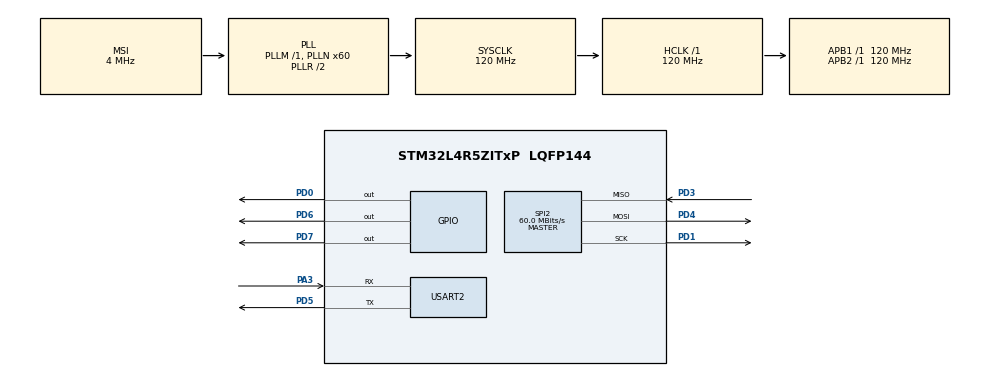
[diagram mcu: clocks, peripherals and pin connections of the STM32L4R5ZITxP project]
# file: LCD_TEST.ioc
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Mcu.Family=STM32L4
Mcu.Name=STM32L4R5ZITxP
Mcu.Package=LQFP144
NVIC.PriorityGroup=NVIC_PRIORITYGROUP_4
PA3.Mode=Asynchronous
PA3.Signal=USART2_RX
PD0.Signal=GPIO_Output
PD1.Mode=Full_Duplex_Master
PD1.Signal=SPI2_SCK
PD3.Mode=Full_Duplex_Master
PD3.Signal=SPI2_MISO
PD4.Mode=Full_Duplex_Master
PD4.Signal=SPI2_MOSI
PD5.Mode=Asynchronous
PD5.Signal=USART2_TX
PD6.Signal=GPIO_Output
PD7.Signal=GPIO_Output
ProjectManager.HeapSize=0x200
ProjectManager.StackSize=0x400
ProjectManager.TargetToolchain=STM32CubeIDE
RCC.ADCFreq_Value=16000000
RCC.AHBFreq_Value=120000000
RCC.APB1Freq_Value=120000000
RCC.APB1TimFreq_Value=120000000
RCC.APB2Freq_Value=120000000
RCC.APB2TimFreq_Value=120000000
RCC.CortexFreq_Value=120000000
RCC.HCLKFreq_Value=120000000
RCC.HSE_VALUE=8000000
RCC.HSI48_VALUE=48000000
RCC.HSI_VALUE=16000000
RCC.LSE_VALUE=32768
RCC.MSI_VALUE=4000000
RCC.PLLN=60
RCC.SYSCLKFreq_VALUE=120000000
RCC.SYSCLKSource=RCC_SYSCLKSOURCE_PLLCLK
RCC.USBFreq_Value=16000000
RCC.VCOOutputFreq_Value=240000000
SPI2.BaudRatePrescaler=SPI_BAUDRATEPRESCALER_2
SPI2.CLKPhase=SPI_PHASE_1EDGE
SPI2.CLKPolarity=SPI_POLARITY_LOW
SPI2.CalculateBaudRate=60.0 MBits/s
SPI2.DataSize=SPI_DATASIZE_8BIT
SPI2.Direction=SPI_DIRECTION_2LINES
SPI2.Mode=SPI_MODE_MASTER
SPI2.VirtualType=VM_MASTER
USART2.VirtualMode-Asynchronous=VM_ASYNC
board=custom

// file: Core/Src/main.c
/* USER CODE BEGIN Header */
/**
  ******************************************************************************
  * @file           : main.c
  * @brief          : Main program body
  ******************************************************************************
  * @attention
  *
  * Copyright (c) 2024 STMicroelectronics.
  * All rights reserved.
  *
  * This software is licensed under terms that can be found in the LICENSE file
  * in the root directory of this software component.
  * If no LICENSE file comes with this software, it is provided AS-IS.
  *
  ******************************************************************************
  */
/* USER CODE END Header */
#include "main.h"

SPI_HandleTypeDef hspi2;

UART_HandleTypeDef huart2;

void SystemClock_Config(void);
static void MX_GPIO_Init(void);
static void MX_SPI2_Init(void);
static void MX_USART2_UART_Init(void);

/* USER CODE BEGIN 0 */

/*
//1. Write Command to LCD
void ILI9488_SendCommand(uint8_t com)
{
	//*(__IO uint8_t *)(0x60000000) = com;
	uint8_t tmpCmd = com;
	//Set DC HIGH for COMMAND mode
	//HAL_GPIO_WritePin(tftDC_GPIO, tftDC_PIN, GPIO_PIN_RESET);
	HAL_GPIO_WritePin(GPIOD, GPIO_PIN_6, GPIO_PIN_RESET);
	//Put CS LOW
	HAL_GPIO_WritePin(GPIOD, GPIO_PIN_0, GPIO_PIN_RESET); //CHIP SELECT
	//Write byte using SPI
	HAL_SPI_Transmit(&hspi2, &tmpCmd, 1, 1);
	//SendByte(tmpCmd);
	//WaitLastData();
	HAL_GPIO_WritePin(GPIOD, GPIO_PIN_0, GPIO_PIN_SET);
	HAL_Delay(1);
	//Bring CS HIGH
	//HAL_GPIO_WritePin(tftCS_GPIO, tftCS_PIN, GPIO_PIN_SET);
}

//2. Write data to LCD
void ILI9488_SendData(uint8_t data)
{
	//*(__IO uint8_t *)(0x60000000) = com;
	uint8_t tmpCmd = data;
	//Set DC HIGH for COMMAND mode
	//HAL_GPIO_WritePin(tftDC_GPIO, tftDC_PIN, GPIO_PIN_RESET);
	HAL_GPIO_WritePin(GPIOD, GPIO_PIN_6, GPIO_PIN_SET);
	//Put CS LOW
	HAL_GPIO_WritePin(GPIOD, GPIO_PIN_0, GPIO_PIN_RESET); //CHIP SELECT
	//Write byte using SPI
	HAL_SPI_Transmit(&hspi2, &tmpCmd, 1, 1);
	//SendByte(tmpCmd);
	//WaitLastData();
	HAL_GPIO_WritePin(GPIOD, GPIO_PIN_0, GPIO_PIN_SET);
	//Bring CS HIGH
	//HAL_GPIO_WritePin(tftCS_GPIO, tftCS_PIN, GPIO_PIN_SET);
}
*/
/* USER CODE END 0 */

int main(void)
{

  /* MCU Configuration--------------------------------------------------------*/

  /* Reset of all peripherals, Initializes the Flash interface and the Systick. */
  HAL_Init();

  /* Configure the system clock */
  SystemClock_Config();

  /* Initialize all configured peripherals */
  MX_GPIO_Init();
  MX_SPI2_Init();
  MX_USART2_UART_Init();
  /* USER CODE BEGIN 2 */

ILI9488_Init();
HAL_Delay(1000);
setRotation(1);

char timereq [2] = {0x10, 0x01};
char buffer [20];

  /* USER CODE END 2 */
fillScreen(ILI9488_WHITE);

  /* Infinite loop */
  /* USER CODE BEGIN WHILE */
  while (1)
  {
	//
	  HAL_UART_Transmit(&huart2, timereq, 2, 100);
	  HAL_UART_Receive(&huart2, buffer, 19, 100);
	  buffer[19] = '\0';
	  ILI9488_printText(buffer, 10, 10, ILI9488_BLACK, ILI9488_WHITE, 2);

	  HAL_Delay(30000);

    /* USER CODE END WHILE */

  }
}

void SystemClock_Config(void)
{
  RCC_OscInitTypeDef RCC_OscInitStruct = {0};
  RCC_ClkInitTypeDef RCC_ClkInitStruct = {0};

  /** Configure the main internal regulator output voltage
  */
  if (HAL_PWREx_ControlVoltageScaling(PWR_REGULATOR_VOLTAGE_SCALE1_BOOST) != HAL_OK)
  {
    Error_Handler();
  }

  /** Initializes the RCC Oscillators according to the specified parameters
  * in the RCC_OscInitTypeDef structure.
  */
  RCC_OscInitStruct.OscillatorType = RCC_OSCILLATORTYPE_MSI;
  RCC_OscInitStruct.MSIState = RCC_MSI_ON;
  RCC_OscInitStruct.MSICalibrationValue = 0;
  RCC_OscInitStruct.MSIClockRange = RCC_MSIRANGE_6;
  RCC_OscInitStruct.PLL.PLLState = RCC_PLL_ON;
  RCC_OscInitStruct.PLL.PLLSource = RCC_PLLSOURCE_MSI;
  RCC_OscInitStruct.PLL.PLLM = 1;
  RCC_OscInitStruct.PLL.PLLN = 60;
  RCC_OscInitStruct.PLL.PLLP = RCC_PLLP_DIV2;
  RCC_OscInitStruct.PLL.PLLQ = RCC_PLLQ_DIV2;
  RCC_OscInitStruct.PLL.PLLR = RCC_PLLR_DIV2;
  if (HAL_RCC_OscConfig(&RCC_OscInitStruct) != HAL_OK)
  {
    Error_Handler();
  }

  /** Initializes the CPU, AHB and APB buses clocks
  */
  RCC_ClkInitStruct.ClockType = RCC_CLOCKTYPE_HCLK|RCC_CLOCKTYPE_SYSCLK
                              |RCC_CLOCKTYPE_PCLK1|RCC_CLOCKTYPE_PCLK2;
  RCC_ClkInitStruct.SYSCLKSource = RCC_SYSCLKSOURCE_PLLCLK;
  RCC_ClkInitStruct.AHBCLKDivider = RCC_SYSCLK_DIV1;
  RCC_ClkInitStruct.APB1CLKDivider = RCC_HCLK_DIV1;
  RCC_ClkInitStruct.APB2CLKDivider = RCC_HCLK_DIV1;

  if (HAL_RCC_ClockConfig(&RCC_ClkInitStruct, FLASH_LATENCY_5) != HAL_OK)
  {
    Error_Handler();
  }
}

static void MX_SPI2_Init(void)
{

  /* SPI2 parameter configuration*/
  hspi2.Instance = SPI2;
  hspi2.Init.Mode = SPI_MODE_MASTER;
  hspi2.Init.Direction = SPI_DIRECTION_2LINES;
  hspi2.Init.DataSize = SPI_DATASIZE_8BIT;
  hspi2.Init.CLKPolarity = SPI_POLARITY_LOW;
  hspi2.Init.CLKPhase = SPI_PHASE_1EDGE;
  hspi2.Init.NSS = SPI_NSS_SOFT;
  hspi2.Init.BaudRatePrescaler = SPI_BAUDRATEPRESCALER_2;
  hspi2.Init.FirstBit = SPI_FIRSTBIT_MSB;
  hspi2.Init.TIMode = SPI_TIMODE_DISABLE;
  hspi2.Init.CRCCalculation = SPI_CRCCALCULATION_DISABLE;
  hspi2.Init.CRCPolynomial = 7;
  hspi2.Init.CRCLength = SPI_CRC_LENGTH_DATASIZE;
  hspi2.Init.NSSPMode = SPI_NSS_PULSE_ENABLE;
  if (HAL_SPI_Init(&hspi2) != HAL_OK)
  {
    Error_Handler();
  }

}

static void MX_USART2_UART_Init(void)
{

  huart2.Instance = USART2;
  huart2.Init.BaudRate = 115200;
  huart2.Init.WordLength = UART_WORDLENGTH_8B;
  huart2.Init.StopBits = UART_STOPBITS_1;
  huart2.Init.Parity = UART_PARITY_NONE;
  huart2.Init.Mode = UART_MODE_TX_RX;
  huart2.Init.HwFlowCtl = UART_HWCONTROL_NONE;
  huart2.Init.OverSampling = UART_OVERSAMPLING_16;
  huart2.Init.OneBitSampling = UART_ONE_BIT_SAMPLE_DISABLE;
  huart2.Init.ClockPrescaler = UART_PRESCALER_DIV1;
  huart2.AdvancedInit.AdvFeatureInit = UART_ADVFEATURE_NO_INIT;
  if (HAL_UART_Init(&huart2) != HAL_OK)
  {
    Error_Handler();
  }
  if (HAL_UARTEx_SetTxFifoThreshold(&huart2, UART_TXFIFO_THRESHOLD_1_8) != HAL_OK)
  {
    Error_Handler();
  }
  if (HAL_UARTEx_SetRxFifoThreshold(&huart2, UART_RXFIFO_THRESHOLD_1_8) != HAL_OK)
  {
    Error_Handler();
  }
  if (HAL_UARTEx_DisableFifoMode(&huart2) != HAL_OK)
  {
    Error_Handler();
  }

}

static void MX_GPIO_Init(void)
{
  GPIO_InitTypeDef GPIO_InitStruct = {0};

  /* GPIO Ports Clock Enable */
  __HAL_RCC_GPIOA_CLK_ENABLE();
  __HAL_RCC_GPIOD_CLK_ENABLE();

  /*Configure GPIO pin Output Level */
  HAL_GPIO_WritePin(GPIOD, GPIO_PIN_0|GPIO_PIN_6|GPIO_PIN_7, GPIO_PIN_RESET);

  /*Configure GPIO pins : PD0 PD6 PD7 */
  GPIO_InitStruct.Pin = GPIO_PIN_0|GPIO_PIN_6|GPIO_PIN_7;
  GPIO_InitStruct.Mode = GPIO_MODE_OUTPUT_PP;
  GPIO_InitStruct.Pull = GPIO_NOPULL;
  GPIO_InitStruct.Speed = GPIO_SPEED_FREQ_LOW;
  HAL_GPIO_Init(GPIOD, &GPIO_InitStruct);

}

void Error_Handler(void)
{
  __disable_irq();
  while (1)
  {
  }
}
